# TM4C129ENCPDT register map
File version: 1.0
CPU: CORTEX_M4 1.0, other endian, MPU, FPU, 3 interrupt priority bits
Registers are 32-bit, read-write, reset 0x0 unless marked. A register's access mark holds for its fields unless they carry their own. Offsets are from the block's base; [hi:lo] are bit positions; {n}, {i} and the like mark numbered series.

## AES — AES register offsets
Base 0x44036000
0x00 AES_KEY2_6
  [31:0] AES_KEY2_6_KEY — [31:0] Key Data
0x04 AES_KEY2_7
  [31:0] AES_KEY2_7_KEY — [31:0] Key Data
0x08 AES_KEY2_4
  [31:0] AES_KEY2_4_KEY — [31:0] Key Data
0x0C AES_KEY2_5
  [31:0] AES_KEY2_5_KEY — [31:0] Key Data
0x10 AES_KEY2_2
  [31:0] AES_KEY2_2_KEY — [31:0] Key Data
0x14 AES_KEY2_3
  [31:0] AES_KEY2_3_KEY — [31:0] Key Data
0x18 AES_KEY2_0
  [31:0] AES_KEY2_0_KEY — [31:0] Key Data
0x1C AES_KEY2_1
  [31:0] AES_KEY2_1_KEY — [31:0] Key Data
0x20 AES_KEY1_6
  [31:0] AES_KEY1_6_KEY — [31:0] Key Data
0x24 AES_KEY1_7
  [31:0] AES_KEY1_7_KEY — [31:0] Key Data
0x28 AES_KEY1_4
  [31:0] AES_KEY1_4_KEY — [31:0] Key Data
0x2C AES_KEY1_5
  [31:0] AES_KEY1_5_KEY — [31:0] Key Data
0x30 AES_KEY1_2
  [31:0] AES_KEY1_2_KEY — [31:0] Key Data
0x34 AES_KEY1_3
  [31:0] AES_KEY1_3_KEY — [31:0] Key Data
0x38 AES_KEY1_0
  [31:0] AES_KEY1_0_KEY — [31:0] Key Data
0x3C AES_KEY1_1
  [31:0] AES_KEY1_1_KEY — [31:0] Key Data
{0x40+4i} AES_IV_IN_{i} (i=0..3) — AES Initialization Vector Input {i}
  [31:0] AES_IV_IN_{i}_DATA — [31:0] Initialization Vector Input
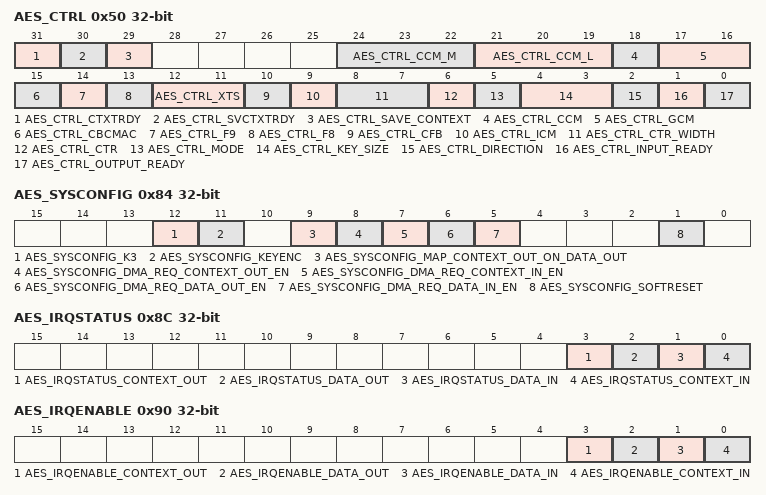
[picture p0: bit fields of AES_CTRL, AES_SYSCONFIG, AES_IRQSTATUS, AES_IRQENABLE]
0x50 AES_CTRL — AES Control
  [31] AES_CTRL_CTXTRDY — [31:31] Context Data Registers Ready
  [30] AES_CTRL_SVCTXTRDY — [30:30] AES TAG/IV Block(s) Ready
  [29] AES_CTRL_SAVE_CONTEXT — [29:29] TAG or Result IV Save
  [24:22] AES_CTRL_CCM_M — [24:22] Counter with CBC-MAC (CCM)
  [21:19] AES_CTRL_CCM_L — [21:19] L Value
    0x80000=width = 2; 0x180000=width = 4; 0x380000=width = 8
  [18] AES_CTRL_CCM — [18:18] AES-CCM Mode Enable
  [17:16] AES_CTRL_GCM — [17:16] AES-GCM Mode Enable
    0=AES_CTRL_GCM_NOP (No operation); 0x10000=AES_CTRL_GCM_HLY0ZERO (GHASH with H loaded and Y0-encrypted forced to zero); 0x20000=AES_CTRL_GCM_HLY0CALC (GHASH with H loaded and Y0-encrypted calculated internally); 0x30000=AES_CTRL_GCM_HY0CALC (Autonomous GHASH (both H and Y0-encrypted calculated internally))
  [15] AES_CTRL_CBCMAC — [15:15] AES-CBC MAC Enable
  [14] AES_CTRL_F9 — [14:14] AES f9 Mode Enable
  [13] AES_CTRL_F8 — [13:13] AES f8 Mode Enable
  [12:11] AES_CTRL_XTS — [12:11] AES-XTS Operation Enabled
    0=AES_CTRL_XTS_NOP (No operation); 0x800=AES_CTRL_XTS_TWEAKJL (Previous/intermediate tweak value and j loaded (value is loaded via IV, j is loaded via the AAD length register)); 0x1000=AES_CTRL_XTS_K2IJL (Key2, n and j are loaded (n is loaded via IV, j is loaded via the AAD length register)); 0x1800=AES_CTRL_XTS_K2ILJ0 (Key2 and n are loaded; j=0 (n is loaded via IV))
  [10] AES_CTRL_CFB — [10:10] Full block AES cipher feedback mode (CFB128) Enable
  [9] AES_CTRL_ICM — [9:9] AES Integer Counter Mode (ICM) Enable
  [8:7] AES_CTRL_CTR_WIDTH — [8:7] AES-CTR Mode Counter Width
    0=Counter is 32 bits; 128=Counter is 64 bits; 0x100=Counter is 96 bits; 0x180=Counter is 128 bits
  [6] AES_CTRL_CTR — [6:6] Counter Mode
  [5] AES_CTRL_MODE — [5:5] ECB/CBC Mode
  [4:3] AES_CTRL_KEY_SIZE — [4:3] Key Size
    8=Key is 128 bits; 16=Key is 192 bits; 24=Key is 256 bits
  [2] AES_CTRL_DIRECTION — [2:2] Encryption/Decryption Selection
  [1] AES_CTRL_INPUT_READY — [1:1] Input Ready Status
  [0] AES_CTRL_OUTPUT_READY — [0:0] Output Ready Status
0x54 AES_C_LENGTH_0 — AES Crypto Data Length 0
  [31:0] AES_C_LENGTH_0_LENGTH — [31:0] Data Length
0x58 AES_C_LENGTH_1 — AES Crypto Data Length 1
  [31:0] AES_C_LENGTH_1_LENGTH — [31:0] Data Length
0x5C AES_AUTH_LENGTH — AES Authentication Data Length
  [31:0] AES_AUTH_LENGTH_AUTH — [31:0] Authentication Data Length
{0x60+4i} AES_DATA_IN_{i} (i=0..3) — AES Data RW Plaintext/Ciphertext {i}
  [31:0] AES_DATA_IN_{i}_DATA — [31:0] Secure Data RW Plaintext/Ciphertext
{0x70+4i} AES_TAG_OUT_{i} (i=0..3) — AES Hash Tag Out {i}
  [31:0] AES_TAG_OUT_{i}_HASH — [31:0] Hash Result
0x80 AES_REVISION — AES IP Revision Identifier
  [31:0] AES_REVISION — [31:0] Revision number
0x84 AES_SYSCONFIG — AES System Configuration
  [12] AES_SYSCONFIG_K3 — [12:12] K3 Select
  [11] AES_SYSCONFIG_KEYENC — [11:11] Key Encoding
  [9] AES_SYSCONFIG_MAP_CONTEXT_OUT_ON_DATA_OUT — [9:9] Map Context Out on Data Out Enable
  [8] AES_SYSCONFIG_DMA_REQ_CONTEXT_OUT_EN — [8:8] DMA Request Context Out Enable
  [7] AES_SYSCONFIG_DMA_REQ_CONTEXT_IN_EN — [7:7] DMA Request Context In Enable
  [6] AES_SYSCONFIG_DMA_REQ_DATA_OUT_EN — [6:6] DMA Request Data Out Enable
  [5] AES_SYSCONFIG_DMA_REQ_DATA_IN_EN — [5:5] DMA Request Data In Enable
  [1] AES_SYSCONFIG_SOFTRESET — [1:1] Soft reset
0x88 AES_SYSSTATUS — AES System Status
  [0] AES_SYSSTATUS_RESETDONE — [0:0] Reset Done
0x8C AES_IRQSTATUS — AES Interrupt Status
  [3] AES_IRQSTATUS_CONTEXT_OUT — [3:3] Context Output Interrupt Status
  [2] AES_IRQSTATUS_DATA_OUT — [2:2] Data Out Interrupt Status
  [1] AES_IRQSTATUS_DATA_IN — [1:1] Data In Interrupt Status
  [0] AES_IRQSTATUS_CONTEXT_IN — [0:0] Context In Interrupt Status
0x90 AES_IRQENABLE — AES Interrupt Enable
  [3] AES_IRQENABLE_CONTEXT_OUT — [3:3] Context Out Interrupt Enable
  [2] AES_IRQENABLE_DATA_OUT — [2:2] Data Out Interrupt Enable
  [1] AES_IRQENABLE_DATA_IN — [1:1] Data In Interrupt Enable
  [0] AES_IRQENABLE_CONTEXT_IN — [0:0] Context In Interrupt Enable
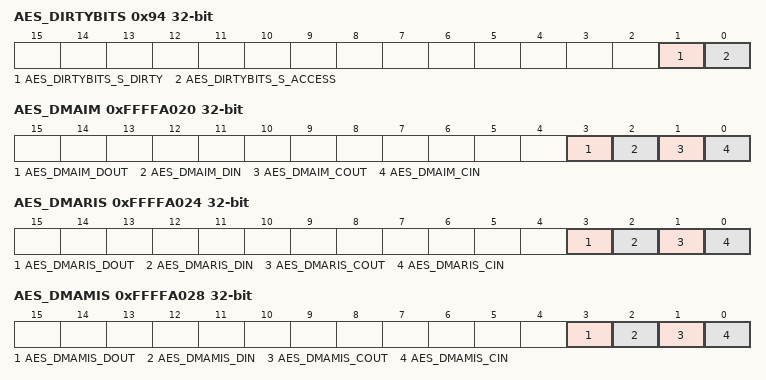
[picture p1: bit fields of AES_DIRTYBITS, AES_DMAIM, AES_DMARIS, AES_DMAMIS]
0x94 AES_DIRTYBITS
  [1] AES_DIRTYBITS_S_DIRTY — [1:1] AES Dirty Bit
  [0] AES_DIRTYBITS_S_ACCESS — [0:0] AES Access Bit
0xFFFFA020 AES_DMAIM — AES DMA Interrupt Mask
  [3] AES_DMAIM_DOUT — [3:3] Data Out DMA Done Interrupt Mask
  [2] AES_DMAIM_DIN — [2:2] Data In DMA Done Interrupt Mask
  [1] AES_DMAIM_COUT — [1:1] Context Out DMA Done Interrupt Mask
  [0] AES_DMAIM_CIN — [0:0] Context In DMA Done Interrupt Mask
0xFFFFA024 AES_DMARIS — AES DMA Raw Interrupt Status
  [3] AES_DMARIS_DOUT — [3:3] Data Out DMA Done Raw Interrupt Status
  [2] AES_DMARIS_DIN — [2:2] Data In DMA Done Raw Interrupt Status
  [1] AES_DMARIS_COUT — [1:1] Context Out DMA Done Raw Interrupt Status
  [0] AES_DMARIS_CIN — [0:0] Context In DMA Done Raw Interrupt Status
0xFFFFA028 AES_DMAMIS — AES DMA Masked Interrupt Status
  [3] AES_DMAMIS_DOUT — [3:3] Data Out DMA Done Masked Interrupt Status
  [2] AES_DMAMIS_DIN — [2:2] Data In DMA Done Masked Interrupt Status
  [1] AES_DMAMIS_COUT — [1:1] Context Out DMA Done Masked Interrupt Status
  [0] AES_DMAMIS_CIN — [0:0] Context In DMA Done Raw Interrupt Status
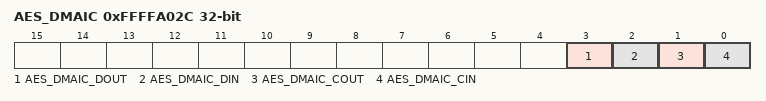
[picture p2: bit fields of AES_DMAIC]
0xFFFFA02C AES_DMAIC — AES DMA Interrupt Clear
  [3] AES_DMAIC_DOUT — [3:3] Data Out DMA Done Interrupt Clear
  [2] AES_DMAIC_DIN — [2:2] Data In DMA Done Interrupt Clear
  [1] AES_DMAIC_COUT — [1:1] Context Out DMA Done Masked Interrupt Status
  [0] AES_DMAIC_CIN — [0:0] Context In DMA Done Raw Interrupt Status
